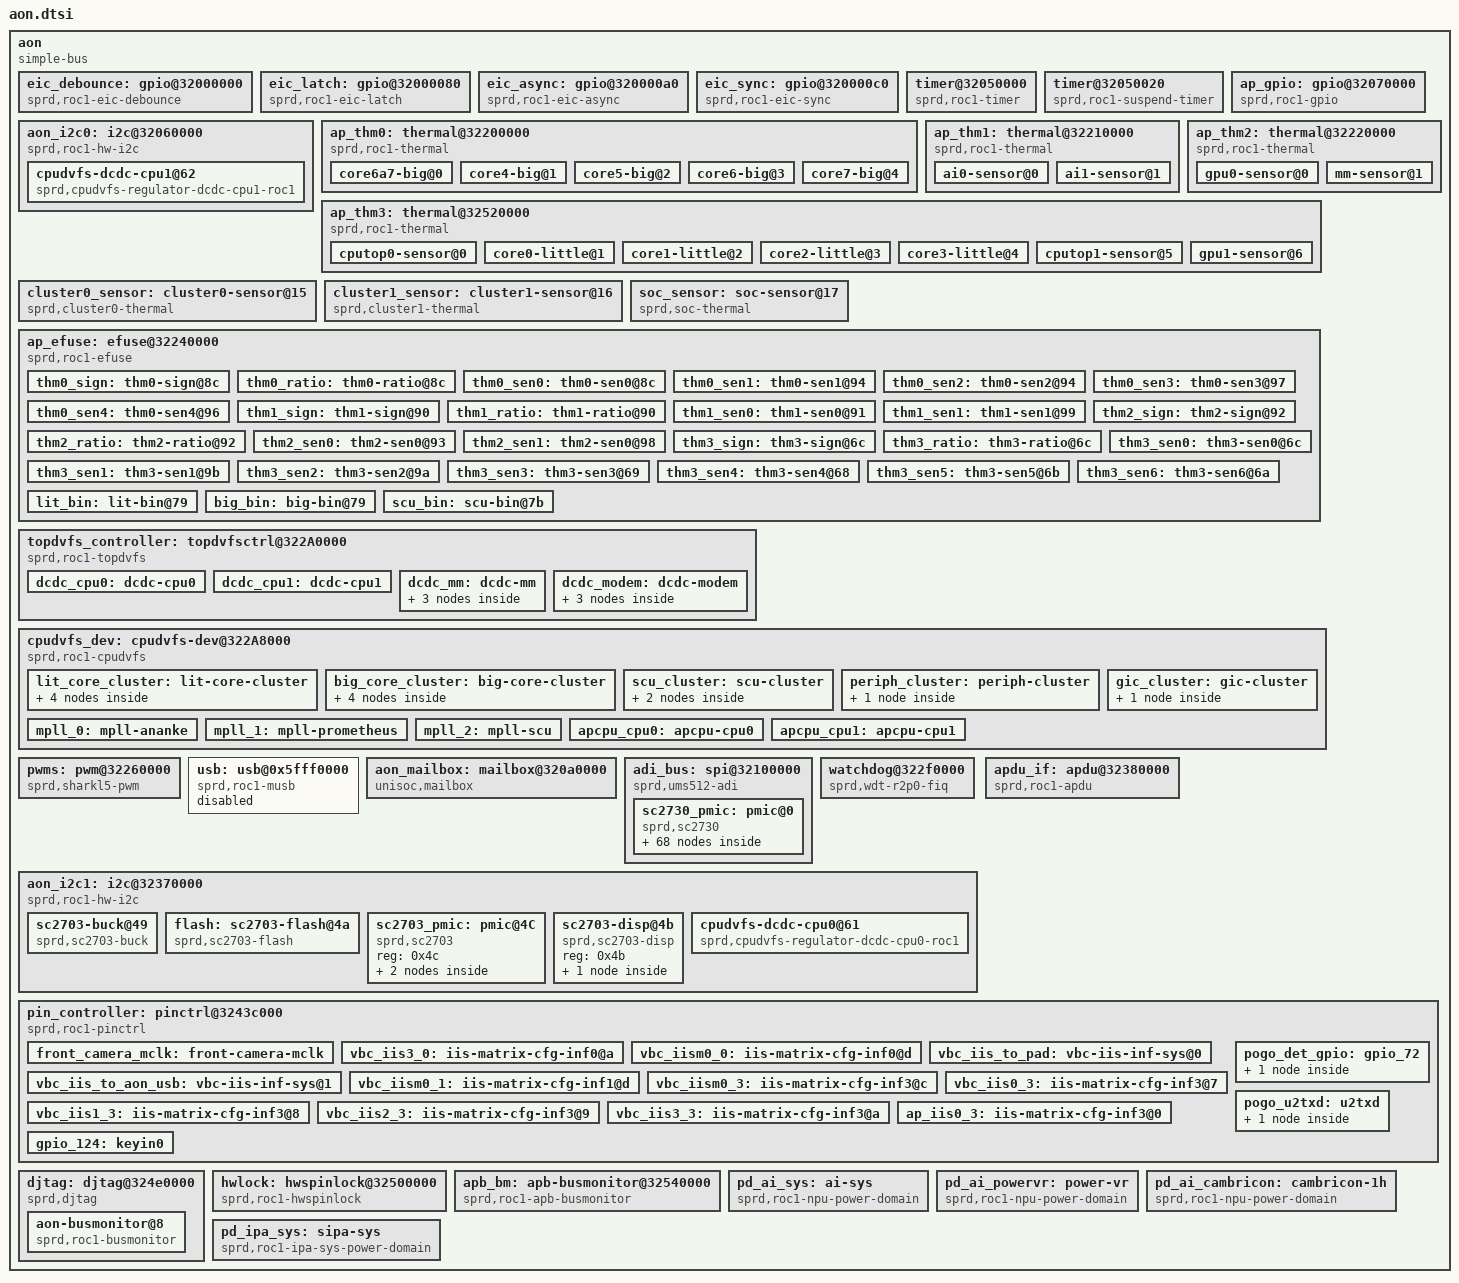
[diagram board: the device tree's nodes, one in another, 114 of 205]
/*
 * iclass-c8pro hardware description; included in place from the board DTS.
 * Copyright (C) 2026 Evarentha - Linux 5.15 board port changes.
 */

		aon {
			compatible = "simple-bus";
			#address-cells = <0x02>;
			#size-cells = <0x02>;
			ranges;

			eic_debounce: gpio@32000000 {
				compatible = "sprd,roc1-eic-debounce";
				reg = <0x00 0x32000000 0x00 0x80 0x00 0x32010000 0x00 0x80 0x00 0x32020000 0x00 0x80 0x00 0x32030000 0x00 0x80 0x00 0x32230000 0x00 0x80 0x00 0x32270000 0x00 0x80>;
				gpio-controller;
				#gpio-cells = <0x02>;
				interrupt-controller;
				#interrupt-cells = <0x02>;
				interrupts = <0x00 0x48 0x04>;
				phandle = <0x157>;
			};

			eic_latch: gpio@32000080 {
				compatible = "sprd,roc1-eic-latch";
				reg = <0x00 0x32000080 0x00 0x20 0x00 0x32010080 0x00 0x20 0x00 0x32020080 0x00 0x20 0x00 0x32030080 0x00 0x20 0x00 0x32230080 0x00 0x20 0x00 0x32270080 0x00 0x20>;
				gpio-controller;
				#gpio-cells = <0x02>;
				interrupt-controller;
				#interrupt-cells = <0x02>;
				interrupts = <0x00 0x48 0x04>;
				phandle = <0x158>;
			};

			eic_async: gpio@320000a0 {
				compatible = "sprd,roc1-eic-async";
				reg = <0x00 0x320000a0 0x00 0x20 0x00 0x320100a0 0x00 0x20 0x00 0x320200a0 0x00 0x20 0x00 0x320300a0 0x00 0x20 0x00 0x322300a0 0x00 0x20 0x00 0x322700a0 0x00 0x20>;
				gpio-controller;
				#gpio-cells = <0x02>;
				interrupt-controller;
				#interrupt-cells = <0x02>;
				interrupts = <0x00 0x48 0x04>;
				phandle = <0x35>;
			};

			eic_sync: gpio@320000c0 {
				compatible = "sprd,roc1-eic-sync";
				reg = <0x00 0x320000c0 0x00 0x20 0x00 0x320100c0 0x00 0x20 0x00 0x320200c0 0x00 0x20 0x00 0x320300c0 0x00 0x20 0x00 0x322300c0 0x00 0x20 0x00 0x322700c0 0x00 0x20>;
				gpio-controller;
				#gpio-cells = <0x02>;
				interrupt-controller;
				#interrupt-cells = <0x02>;
				interrupts = <0x00 0x48 0x04>;
				phandle = <0x159>;
			};

			timer@32050000 {
				compatible = "sprd,roc1-timer";
				reg = <0x00 0x32050000 0x00 0x20>;
				interrupts = <0x00 0x47 0x04>;
				clocks = <0x25>;
			};

			timer@32050020 {
				compatible = "sprd,roc1-suspend-timer";
				reg = <0x00 0x32050020 0x00 0x20>;
				clocks = <0x25>;
			};

			aon_i2c0: i2c@32060000 {
				compatible = "sprd,roc1-hw-i2c";
				reg = <0x00 0x32060000 0x00 0x1000>;
				interrupts = <0x00 0x44 0x04>;
				clock-names = "source", "enable", "i2c";
				clocks = <&ext_26m>, <&aonapb_gate 0x2c>,
					 <&aon_clk 0x11>;
				clock-frequency = <0x61a80>;
				#address-cells = <0x01>;
				#size-cells = <0x00>;
				status = "okay";
				phandle = <0x15a>;

				cpudvfs-dcdc-cpu1@62 {
					compatible = "sprd,cpudvfs-regulator-dcdc-cpu1-roc1";
					reg = <0x62>;
					dvfs-dcdc-i2c = <0x01>;
				};
			};

			ap_gpio: gpio@32070000 {
				compatible = "sprd,roc1-gpio";
				reg = <0x00 0x32070000 0x00 0x10000>;
				gpio-controller;
				#gpio-cells = <0x02>;
				interrupt-controller;
				#interrupt-cells = <0x02>;
				interrupts = <0x00 0x3d 0x04>;
				phandle = <0x2d>;
			};

			ap_thm0: thermal@32200000 {
				compatible = "sprd,roc1-thermal";
				reg = <0x00 0x32200000 0x00 0x10000>;
				clock-names = "enable";
				clocks = <0x04 0x28>;
				#thermal-sensor-cells = <0x01>;
				nvmem-cells = <0x3b 0x3c>;
				nvmem-cell-names = "thm_sign_cal", "thm_ratio_cal";
				phandle = <0x10c>;

				core6a7-big@0 {
					reg = <0x00>;
					nvmem-cells = <0x3d>;
					nvmem-cell-names = "sen_delta_cal";
				};

				core4-big@1 {
					reg = <0x01>;
					nvmem-cells = <0x3e>;
					nvmem-cell-names = "sen_delta_cal";
				};

				core5-big@2 {
					reg = <0x02>;
					nvmem-cells = <0x3f>;
					nvmem-cell-names = "sen_delta_cal";
				};

				core6-big@3 {
					reg = <0x03>;
					nvmem-cells = <0x40>;
					nvmem-cell-names = "sen_delta_cal";
				};

				core7-big@4 {
					reg = <0x04>;
					nvmem-cells = <0x41>;
					nvmem-cell-names = "sen_delta_cal";
				};
			};

			ap_thm1: thermal@32210000 {
				compatible = "sprd,roc1-thermal";
				reg = <0x00 0x32210000 0x00 0x10000>;
				clock-names = "enable";
				clocks = <0x04 0x29>;
				#thermal-sensor-cells = <0x01>;
				nvmem-cells = <0x42 0x43>;
				nvmem-cell-names = "thm_sign_cal", "thm_ratio_cal";
				phandle = <0x10d>;

				ai0-sensor@0 {
					reg = <0x00>;
					nvmem-cells = <0x44>;
					nvmem-cell-names = "sen_delta_cal";
				};

				ai1-sensor@1 {
					reg = <0x01>;
					nvmem-cells = <0x45>;
					nvmem-cell-names = "sen_delta_cal";
				};
			};

			ap_thm2: thermal@32220000 {
				compatible = "sprd,roc1-thermal";
				reg = <0x00 0x32220000 0x00 0x10000>;
				clock-names = "enable";
				clocks = <0x04 0x2a>;
				#thermal-sensor-cells = <0x01>;
				nvmem-cells = <0x46 0x47>;
				nvmem-cell-names = "thm_sign_cal", "thm_ratio_cal";
				phandle = <0x10e>;

				gpu0-sensor@0 {
					reg = <0x00>;
					nvmem-cells = <0x48>;
					nvmem-cell-names = "sen_delta_cal";
				};

				mm-sensor@1 {
					reg = <0x01>;
					nvmem-cells = <0x49>;
					nvmem-cell-names = "sen_delta_cal";
				};
			};

			ap_thm3: thermal@32520000 {
				compatible = "sprd,roc1-thermal";
				reg = <0x00 0x32520000 0x00 0x10000>;
				clock-names = "enable";
				clocks = <0x04 0x23>;
				#thermal-sensor-cells = <0x01>;
				nvmem-cells = <0x4a 0x4b>;
				nvmem-cell-names = "thm_sign_cal", "thm_ratio_cal";
				phandle = <0x10f>;

				cputop0-sensor@0 {
					reg = <0x00>;
					nvmem-cells = <0x4c>;
					nvmem-cell-names = "sen_delta_cal";
				};

				core0-little@1 {
					reg = <0x01>;
					nvmem-cells = <0x4d>;
					nvmem-cell-names = "sen_delta_cal";
				};

				core1-little@2 {
					reg = <0x02>;
					nvmem-cells = <0x4e>;
					nvmem-cell-names = "sen_delta_cal";
				};

				core2-little@3 {
					reg = <0x03>;
					nvmem-cells = <0x4f>;
					nvmem-cell-names = "sen_delta_cal";
				};

				core3-little@4 {
					reg = <0x04>;
					nvmem-cells = <0x50>;
					nvmem-cell-names = "sen_delta_cal";
				};

				cputop1-sensor@5 {
					reg = <0x05>;
					nvmem-cells = <0x51>;
					nvmem-cell-names = "sen_delta_cal";
				};

				gpu1-sensor@6 {
					reg = <0x06>;
					nvmem-cells = <0x52>;
					nvmem-cell-names = "sen_delta_cal";
				};
			};

			cluster0_sensor: cluster0-sensor@15 {
				compatible = "sprd,cluster0-thermal";
				#thermal-sensor-cells = <0x01>;
				sensor-names = "littlecore0-thmzone", "littlecore1-thmzone", "littlecore2-thmzone", "littlecore3-thmzone";
				k-po = <0x80>;
				k-pu = <0x100>;
				k-i = <0x02>;
				k-d = <0x00>;
				cutoff = <0x2710>;
				phandle = <0x110>;
			};

			cluster1_sensor: cluster1-sensor@16 {
				compatible = "sprd,cluster1-thermal";
				#thermal-sensor-cells = <0x01>;
				sensor-names = "bigcore4-thmzone", "bigcore5-thmzone", "bigcore6-thmzone", "bigcore7-thmzone";
				k-po = <0x80>;
				k-pu = <0x100>;
				k-i = <0x02>;
				k-d = <0x00>;
				cutoff = <0x2710>;
				phandle = <0x111>;
			};

			soc_sensor: soc-sensor@17 {
				compatible = "sprd,soc-thermal";
				#thermal-sensor-cells = <0x01>;
				sensor-names = "cluster0-thmzone", "cluster1-thmzone";
				k-po = <0x00>;
				k-pu = <0x00>;
				k-i = <0x02>;
				k-d = <0x00>;
				cutoff = <0x00>;
				phandle = <0x108>;
			};

			ap_efuse: efuse@32240000 {
				compatible = "sprd,roc1-efuse";
				reg = <0x00 0x32240000 0x00 0x10000>;
				clock-names = "enable";
				hwlocks = <0x53 0x08>;
				clocks = <0x04 0x13>;
				phandle = <0x15b>;

				thm0_sign: thm0-sign@8c {
					reg = <0x8c 0x04>;
					bits = <0x00 0x01>;
					phandle = <0x3b>;
				};

				thm0_ratio: thm0-ratio@8c {
					reg = <0x8c 0x04>;
					bits = <0x01 0x07>;
					phandle = <0x3c>;
				};

				thm0_sen0: thm0-sen0@8c {
					reg = <0x8d 0x04>;
					bits = <0x00 0x08>;
					phandle = <0x3d>;
				};

				thm0_sen1: thm0-sen1@94 {
					reg = <0x95 0x04>;
					bits = <0x00 0x08>;
					phandle = <0x3e>;
				};

				thm0_sen2: thm0-sen2@94 {
					reg = <0x94 0x04>;
					bits = <0x00 0x08>;
					phandle = <0x3f>;
				};

				thm0_sen3: thm0-sen3@97 {
					reg = <0x97 0x04>;
					bits = <0x00 0x08>;
					phandle = <0x40>;
				};

				thm0_sen4: thm0-sen4@96 {
					reg = <0x96 0x04>;
					bits = <0x00 0x08>;
					phandle = <0x41>;
				};

				thm1_sign: thm1-sign@90 {
					reg = <0x90 0x04>;
					bits = <0x00 0x01>;
					phandle = <0x42>;
				};

				thm1_ratio: thm1-ratio@90 {
					reg = <0x90 0x04>;
					bits = <0x01 0x07>;
					phandle = <0x43>;
				};

				thm1_sen0: thm1-sen0@91 {
					reg = <0x91 0x04>;
					bits = <0x00 0x08>;
					phandle = <0x44>;
				};

				thm1_sen1: thm1-sen1@99 {
					reg = <0x99 0x04>;
					bits = <0x00 0x08>;
					phandle = <0x45>;
				};

				thm2_sign: thm2-sign@92 {
					reg = <0x92 0x04>;
					bits = <0x00 0x01>;
					phandle = <0x46>;
				};

				thm2_ratio: thm2-ratio@92 {
					reg = <0x92 0x04>;
					bits = <0x01 0x07>;
					phandle = <0x47>;
				};

				thm2_sen0: thm2-sen0@93 {
					reg = <0x93 0x04>;
					bits = <0x00 0x08>;
					phandle = <0x48>;
				};

				thm2_sen1: thm2-sen0@98 {
					reg = <0x98 0x04>;
					bits = <0x00 0x08>;
					phandle = <0x49>;
				};

				thm3_sign: thm3-sign@6c {
					reg = <0x6c 0x04>;
					bits = <0x00 0x01>;
					phandle = <0x4a>;
				};

				thm3_ratio: thm3-ratio@6c {
					reg = <0x6c 0x04>;
					bits = <0x01 0x07>;
					phandle = <0x4b>;
				};

				thm3_sen0: thm3-sen0@6c {
					reg = <0x6d 0x04>;
					bits = <0x00 0x08>;
					phandle = <0x4c>;
				};

				thm3_sen1: thm3-sen1@9b {
					reg = <0x9b 0x04>;
					bits = <0x00 0x08>;
					phandle = <0x4d>;
				};

				thm3_sen2: thm3-sen2@9a {
					reg = <0x9a 0x04>;
					bits = <0x00 0x08>;
					phandle = <0x4e>;
				};

				thm3_sen3: thm3-sen3@69 {
					reg = <0x69 0x04>;
					bits = <0x00 0x08>;
					phandle = <0x4f>;
				};

				thm3_sen4: thm3-sen4@68 {
					reg = <0x68 0x04>;
					bits = <0x00 0x08>;
					phandle = <0x50>;
				};

				thm3_sen5: thm3-sen5@6b {
					reg = <0x6b 0x04>;
					bits = <0x00 0x08>;
					phandle = <0x51>;
				};

				thm3_sen6: thm3-sen6@6a {
					reg = <0x6a 0x04>;
					bits = <0x00 0x08>;
					phandle = <0x52>;
				};

				lit_bin: lit-bin@79 {
					reg = <0x79 0x01>;
					bits = <0x00 0x04>;
					phandle = <0xeb>;
				};

				big_bin: big-bin@79 {
					reg = <0x79 0x01>;
					bits = <0x04 0x04>;
					phandle = <0xec>;
				};

				scu_bin: scu-bin@7b {
					reg = <0x7b 0x01>;
					bits = <0x04 0x04>;
					phandle = <0xed>;
				};
			};

			topdvfs_controller: topdvfsctrl@322A0000 {
				compatible = "sprd,roc1-topdvfs", "syscon";
				sprd,syscon-enable = <0x10>;
				module-enable-cfg = <0x04 0x07>;
				reg = <0x00 0x322a0000 0x00 0x8000>;
				cpu-dcdc-cells = <0x54 0x55>;
				device-dcdc-cells = <0x56 0x57>;
				phandle = <0x60>;

				dcdc_cpu0: dcdc-cpu0 {
					dcdc-dvfs-enable = <0x90 0x00 0x01>;
					dcdc-judge-vol-sw = <0x150 0x0f 0x07 0x00>;
					dcdc-subsys-tune-enable = <0x300 0x02 0x01>;
					dcdc-supply-mode-cfg = <0x58>;
					sync-dcdc-idle-voltage;
					dcdc-idle-voltage = <0x320 0x06 0x07 0x05>;
					phandle = <0x54>;
				};

				dcdc_cpu1: dcdc-cpu1 {
					dcdc-dvfs-enable = <0xa0 0x00 0x01>;
					dcdc-judge-vol-sw = <0x160 0x0f 0x07 0x00>;
					dcdc-subsys-tune-enable = <0x300 0x01 0x01>;
					dcdc-supply-mode-cfg = <0x59>;
					sync-dcdc-idle-voltage;
					dcdc-idle-voltage = <0x320 0x03 0x07 0x05>;
					phandle = <0x55>;
				};

				dcdc_mm: dcdc-mm {
					dcdc-dvfs-enable = <0x18 0x14 0x01>;
					dcdc-judge-vol-sw = <0x18 0x01 0x07 0x02>;
					dcdc-subsys-cells = <0x5a 0x5b 0x5c>;
					phandle = <0x56>;

					audcp_sys: audcp-sys {
						dcdc-subsys-tune-enable = <0x300 0x06 0x01>;
						phandle = <0x5a>;
					};

					gpu_sys: gpu-sys {
						dcdc-subsys-tune-enable = <0x300 0x08 0x01>;
						phandle = <0x5b>;
					};

					mm_sys: mm-sys {
						dcdc-subsys-tune-enable = <0x300 0x07 0x01>;
						phandle = <0x5c>;
					};
				};

				dcdc_modem: dcdc-modem {
					dcdc-dvfs-enable = <0x48 0x14 0x01>;
					dcdc-judge-vol-sw = <0x48 0x01 0x07 0x02>;
					dcdc-subsys-cells = <0x5d 0x5e 0x5f>;
					phandle = <0x57>;

					pubcp_sys: pubcp-sys {
						dcdc-subsys-tune-enable = <0x300 0x03 0x00>;
						phandle = <0x5d>;
					};

					wtlcp_sys: wtlcp-sys {
						dcdc-subsys-tune-enable = <0x300 0x04 0x00>;
						phandle = <0x5e>;
					};

					ap_sys: ap-sys {
						dcdc-subsys-tune-enable = <0x300 0x05 0x01>;
						phandle = <0x5f>;
					};
				};
			};

			cpudvfs_dev: cpudvfs-dev@322A8000 {
				compatible = "sprd,roc1-cpudvfs";
				sprd,syscon-enable = <0x10>;
				module-enable-cfg = <0x04 0x07>;
				topdvfs-controller = <0x60>;
				reg = <0x00 0x322a8000 0x00 0x1000>;
				mpll-cells = <0x61 0x62 0x63>;
				apcpu-dvfs-dcdc-cells = <0x64 0x65>;
				cpudvfs-clusters = <0x66 0x67 0x68 0x69 0x6a>;
				phandle = <0x15c>;

				lit_core_cluster: lit-core-cluster {
					cluster-name = "lit-core-cluster";
					row-num = <0x10>;
					column-num = <0x07>;
					work-index-cfg = <0x214 0x0f>;
					idle-index-cfg = <0x218 0x0f>;
					tuning-latency-us = <0xc8>;
					tuning-result-judge = <0x00>;
					dcdc-name = "DCDC_CPU0";
					map-tbl-regs = <0x60 0x64 0x68 0x6c 0x70 0x74 0x78 0x7c 0x80 0x84 0x88 0x8c 0x90 0x94 0x98 0x9c>;
					column-entry-start-bit = <0x00 0x02 0x0f 0x05 0x09 0x12 0x0c>;
					column-entry-mask = <0x03 0x07 0x07 0x0f 0x07 0x07 0x07>;
					cluster-devices = <0x6b 0x6c 0x6d 0x6e>;
					lit-core-dvfs-tbl = <0x00 0x00 0x00 0x00 0x00 0x00 0x00 0x02 0x01 0x00 0x01 0x01 0x01 0x00 0x01 0x00 0x00 0x01 0x01 0x01 0x00 0x03 0x00 0x01 0x02 0x01 0x01 0x00 0x03 0x00 0x02 0x03 0x02 0x02 0x01 0x02 0x00 0x03 0x04 0x02 0x02 0x00 0x03 0x00 0x04 0x05 0x02 0x03 0x02 0x03 0x00 0x05 0x06 0x02 0x03 0x03 0x03 0x00 0x06 0x07 0x02 0x03 0x04 0x03 0x00 0x07 0x08 0x02 0x03 0x05 0x03 0x00 0x07 0x08 0x02 0x03 0x05 0x03 0x00 0x07 0x08 0x02 0x03 0x05 0x03 0x00 0x07 0x08 0x02 0x03 0x05 0x03 0x00 0x07 0x08 0x02 0x03 0x05 0x03 0x00 0x07 0x08 0x02 0x03 0x05 0x03 0x00 0x07 0x08 0x02 0x03 0x05>;
					lit-core-dvfs-tbl-1 = <0x00 0x00 0x00 0x00 0x00 0x00 0x00 0x02 0x01 0x00 0x01 0x01 0x01 0x00 0x01 0x00 0x00 0x01 0x01 0x01 0x00 0x03 0x00 0x00 0x02 0x01 0x01 0x00 0x03 0x00 0x00 0x03 0x02 0x02 0x01 0x02 0x00 0x01 0x04 0x02 0x02 0x00 0x03 0x00 0x02 0x05 0x02 0x03 0x02 0x03 0x00 0x03 0x06 0x02 0x03 0x03 0x03 0x00 0x04 0x07 0x02 0x03 0x04 0x03 0x00 0x05 0x08 0x02 0x03 0x05 0x03 0x00 0x05 0x08 0x02 0x03 0x05 0x03 0x00 0x05 0x08 0x02 0x03 0x05 0x03 0x00 0x05 0x08 0x02 0x03 0x05 0x03 0x00 0x05 0x08 0x02 0x03 0x05 0x03 0x00 0x05 0x08 0x02 0x03 0x05 0x03 0x00 0x05 0x08 0x02 0x03 0x05>;
					lit-core-dvfs-tbl-2 = <0x00 0x00 0x00 0x00 0x00 0x00 0x00 0x02 0x01 0x00 0x01 0x01 0x01 0x00 0x01 0x00 0x00 0x01 0x01 0x01 0x00 0x03 0x00 0x00 0x02 0x01 0x01 0x00 0x03 0x00 0x01 0x03 0x02 0x02 0x01 0x02 0x00 0x02 0x04 0x02 0x02 0x00 0x03 0x00 0x03 0x05 0x02 0x03 0x02 0x03 0x00 0x04 0x06 0x02 0x03 0x03 0x03 0x00 0x05 0x07 0x02 0x03 0x04 0x03 0x00 0x06 0x08 0x02 0x03 0x05 0x03 0x00 0x06 0x08 0x02 0x03 0x05 0x03 0x00 0x06 0x08 0x02 0x03 0x05 0x03 0x00 0x06 0x08 0x02 0x03 0x05 0x03 0x00 0x06 0x08 0x02 0x03 0x05 0x03 0x00 0x06 0x08 0x02 0x03 0x05 0x03 0x00 0x06 0x08 0x02 0x03 0x05>;
					lit-core-dvfs-tbl-3 = <0x00 0x00 0x00 0x00 0x00 0x00 0x00 0x02 0x01 0x00 0x01 0x01 0x01 0x00 0x01 0x00 0x00 0x01 0x01 0x01 0x00 0x03 0x00 0x00 0x02 0x01 0x01 0x00 0x03 0x00 0x01 0x03 0x02 0x02 0x01 0x02 0x00 0x02 0x04 0x02 0x02 0x00 0x03 0x00 0x03 0x05 0x02 0x03 0x02 0x03 0x00 0x04 0x06 0x02 0x03 0x03 0x03 0x00 0x05 0x07 0x02 0x03 0x04 0x03 0x00 0x06 0x08 0x02 0x03 0x05 0x03 0x00 0x06 0x08 0x02 0x03 0x05 0x03 0x00 0x06 0x08 0x02 0x03 0x05 0x03 0x00 0x06 0x08 0x02 0x03 0x05 0x03 0x00 0x06 0x08 0x02 0x03 0x05 0x03 0x00 0x06 0x08 0x02 0x03 0x05 0x03 0x00 0x06 0x08 0x02 0x03 0x05>;
					lit-core-dvfs-tbl-4 = <0x00 0x00 0x00 0x00 0x00 0x00 0x00 0x02 0x01 0x00 0x01 0x01 0x01 0x00 0x01 0x00 0x00 0x01 0x01 0x01 0x00 0x03 0x00 0x01 0x02 0x01 0x01 0x00 0x03 0x00 0x02 0x03 0x02 0x02 0x01 0x02 0x00 0x03 0x04 0x02 0x02 0x00 0x03 0x00 0x04 0x05 0x02 0x03 0x02 0x03 0x00 0x05 0x06 0x02 0x03 0x03 0x03 0x00 0x06 0x07 0x02 0x03 0x04 0x03 0x00 0x07 0x08 0x02 0x03 0x05 0x03 0x00 0x07 0x08 0x02 0x03 0x05 0x03 0x00 0x07 0x08 0x02 0x03 0x05 0x03 0x00 0x07 0x08 0x02 0x03 0x05 0x03 0x00 0x07 0x08 0x02 0x03 0x05 0x03 0x00 0x07 0x08 0x02 0x03 0x05 0x03 0x00 0x07 0x08 0x02 0x03 0x05>;
					phandle = <0x66>;

					lit_core0_dev: lit-core0-dev {
						device-name = "cpu0";
						sel-get = <0x38 0x00 0x03>;
						div-get = <0x38 0x02 0x07>;
						vol-get = <0x30 0x00 0x07>;
						dfs-idle-disable = <0x308 0x00 0x01>;
						phandle = <0x6b>;
					};

					lit_core1_dev: lit-core1-dev {
						device-name = "cpu1";
						sel-get = <0x38 0x05 0x03>;
						div-get = <0x38 0x07 0x07>;
						vol-get = <0x30 0x03 0x07>;
						dfs-idle-disable = <0x308 0x01 0x01>;
						phandle = <0x6c>;
					};

					lit_core2_dev: lit-core2-dev {
						device-name = "cpu2";
						sel-get = <0x38 0x0a 0x03>;
						div-get = <0x38 0x0c 0x07>;
						vol-get = <0x30 0x06 0x07>;
						dfs-idle-disable = <0x308 0x02 0x01>;
						phandle = <0x6d>;
					};

					lit_core3_dev: lit-core3-dev {
						device-name = "cpu3";
						sel-get = <0x38 0x0f 0x03>;
						div-get = <0x38 0x11 0x07>;
						vol-get = <0x30 0x09 0x07>;
						dfs-idle-disable = <0x308 0x03 0x01>;
						phandle = <0x6e>;
					};
				};

				big_core_cluster: big-core-cluster {
					cluster-name = "big-core-cluster";
					row-num = <0x10>;
					column-num = <0x08>;
					work-index-cfg = <0x224 0x0f>;
					idle-index-cfg = <0x228 0x0f>;
					tuning-latency-us = <0xc8>;
					tuning-result-judge = <0x00>;
					dcdc-name = "DCDC_CPU1";
					map-tbl-regs = <0xa0 0xa4 0xa8 0xac 0xb0 0xb4 0xb8 0xbc 0xc0 0xc4 0xc8 0xcc 0xd0 0xd4 0xd8 0xdc>;
					column-entry-start-bit = <0x00 0x02 0x0f 0x05 0x09 0x12 0x0c 0x15>;
					column-entry-mask = <0x03 0x07 0x07 0x0f 0x07 0x07 0x07 0x07>;
					cluster-devices = <0x6f 0x70 0x71 0x72>;
					big-core-dvfs-tbl = <0x00 0x00 0x00 0x00 0x00 0x00 0x00 0x00 0x01 0x00 0x00 0x03 0x02 0x00 0x00 0x02 0x03 0x00 0x01 0x05 0x02 0x00 0x00 0x03 0x03 0x00 0x02 0x07 0x02 0x00 0x01 0x03 0x03 0x00 0x03 0x08 0x02 0x00 0x02 0x03 0x03 0x00 0x04 0x08 0x02 0x00 0x03 0x03 0x03 0x00 0x05 0x08 0x02 0x00 0x04 0x03 0x03 0x00 0x05 0x08 0x02 0x00 0x04 0x03 0x03 0x00 0x05 0x08 0x02 0x00 0x04 0x03 0x03 0x00 0x05 0x08 0x02 0x00 0x04 0x03 0x03 0x00 0x05 0x08 0x02 0x00 0x04 0x03 0x03 0x00 0x05 0x08 0x02 0x00 0x04 0x03 0x03 0x00 0x05 0x08 0x02 0x00 0x04 0x03 0x03 0x00 0x05 0x08 0x02 0x00 0x04 0x03 0x03 0x00 0x05 0x08 0x02 0x00 0x04 0x03 0x03 0x00 0x05 0x08 0x02 0x00 0x04 0x03>;
					big-core-dvfs-tbl-1 = <0x00 0x00 0x00 0x00 0x00 0x00 0x00 0x00 0x01 0x00 0x00 0x03 0x02 0x00 0x00 0x02 0x03 0x00 0x01 0x05 0x02 0x00 0x00 0x03 0x03 0x00 0x02 0x07 0x02 0x00 0x01 0x03 0x03 0x00 0x03 0x08 0x02 0x00 0x02 0x03 0x03 0x00 0x04 0x08 0x02 0x00 0x03 0x03 0x03 0x00 0x05 0x08 0x02 0x00 0x04 0x03 0x03 0x00 0x05 0x08 0x02 0x00 0x04 0x03 0x03 0x00 0x05 0x08 0x02 0x00 0x04 0x03 0x03 0x00 0x05 0x08 0x02 0x00 0x04 0x03 0x03 0x00 0x05 0x08 0x02 0x00 0x04 0x03 0x03 0x00 0x05 0x08 0x02 0x00 0x04 0x03 0x03 0x00 0x05 0x08 0x02 0x00 0x04 0x03 0x03 0x00 0x05 0x08 0x02 0x00 0x04 0x03 0x03 0x00 0x05 0x08 0x02 0x00 0x04 0x03 0x03 0x00 0x05 0x08 0x02 0x00 0x04 0x03>;
					big-core-dvfs-tbl-2 = <0x00 0x00 0x00 0x00 0x00 0x00 0x00 0x00 0x01 0x00 0x00 0x03 0x02 0x00 0x00 0x02 0x03 0x00 0x01 0x05 0x02 0x00 0x00 0x03 0x03 0x00 0x02 0x07 0x02 0x00 0x01 0x03 0x03 0x00 0x03 0x08 0x02 0x00 0x02 0x03 0x03 0x00 0x04 0x08 0x02 0x00 0x03 0x03 0x03 0x00 0x05 0x08 0x02 0x00 0x04 0x03 0x03 0x00 0x05 0x08 0x02 0x00 0x04 0x03 0x03 0x00 0x05 0x08 0x02 0x00 0x04 0x03 0x03 0x00 0x05 0x08 0x02 0x00 0x04 0x03 0x03 0x00 0x05 0x08 0x02 0x00 0x04 0x03 0x03 0x00 0x05 0x08 0x02 0x00 0x04 0x03 0x03 0x00 0x05 0x08 0x02 0x00 0x04 0x03 0x03 0x00 0x05 0x08 0x02 0x00 0x04 0x03 0x03 0x00 0x05 0x08 0x02 0x00 0x04 0x03 0x03 0x00 0x05 0x08 0x02 0x00 0x04 0x03>;
					big-core-dvfs-tbl-3 = <0x00 0x00 0x00 0x00 0x00 0x00 0x00 0x00 0x01 0x00 0x00 0x03 0x02 0x00 0x00 0x02 0x03 0x00 0x01 0x05 0x02 0x00 0x00 0x03 0x03 0x00 0x02 0x07 0x02 0x00 0x01 0x03 0x03 0x00 0x03 0x08 0x02 0x00 0x02 0x03 0x03 0x00 0x04 0x08 0x02 0x00 0x03 0x03 0x03 0x00 0x05 0x08 0x02 0x00 0x04 0x03 0x03 0x00 0x05 0x08 0x02 0x00 0x04 0x03 0x03 0x00 0x05 0x08 0x02 0x00 0x04 0x03 0x03 0x00 0x05 0x08 0x02 0x00 0x04 0x03 0x03 0x00 0x05 0x08 0x02 0x00 0x04 0x03 0x03 0x00 0x05 0x08 0x02 0x00 0x04 0x03 0x03 0x00 0x05 0x08 0x02 0x00 0x04 0x03 0x03 0x00 0x05 0x08 0x02 0x00 0x04 0x03 0x03 0x00 0x05 0x08 0x02 0x00 0x04 0x03 0x03 0x00 0x05 0x08 0x02 0x00 0x04 0x03>;
					big-core-dvfs-tbl-4 = <0x00 0x00 0x00 0x00 0x00 0x00 0x00 0x00 0x01 0x00 0x00 0x03 0x02 0x00 0x00 0x02 0x03 0x00 0x01 0x05 0x02 0x00 0x00 0x03 0x03 0x00 0x02 0x07 0x02 0x00 0x01 0x03 0x03 0x00 0x03 0x08 0x02 0x00 0x02 0x03 0x03 0x00 0x04 0x08 0x02 0x00 0x03 0x03 0x03 0x00 0x05 0x08 0x02 0x00 0x04 0x03 0x03 0x00 0x05 0x08 0x02 0x00 0x04 0x03 0x03 0x00 0x05 0x08 0x02 0x00 0x04 0x03 0x03 0x00 0x05 0x08 0x02 0x00 0x04 0x03 0x03 0x00 0x05 0x08 0x02 0x00 0x04 0x03 0x03 0x00 0x05 0x08 0x02 0x00 0x04 0x03 0x03 0x00 0x05 0x08 0x02 0x00 0x04 0x03 0x03 0x00 0x05 0x08 0x02 0x00 0x04 0x03 0x03 0x00 0x05 0x08 0x02 0x00 0x04 0x03 0x03 0x00 0x05 0x08 0x02 0x00 0x04 0x03>;
					phandle = <0x67>;

					big_core0_dev: big-core0-dev {
						device-name = "cpu4";
						sel-get = <0x38 0x14 0x03>;
						div-get = <0x38 0x16 0x07>;
						vol-get = <0x30 0x0c 0x07>;
						dfs-idle-disable = <0x308 0x04 0x01>;
						phandle = <0x6f>;
					};

					big_core1_dev: big-core1-dev {
						device-name = "cpu5";
						sel-get = <0x38 0x19 0x03>;
						div-get = <0x38 0x1b 0x07>;
						vol-get = <0x30 0x0f 0x07>;
						dfs-idle-disable = <0x308 0x05 0x01>;
						phandle = <0x70>;
					};

					big_core2_dev: big-core2-dev {
						device-name = "cpu6";
						sel-get = <0x3c 0x00 0x03>;
						div-get = <0x3c 0x02 0x07>;
						vol-get = <0x30 0x12 0x07>;
						dfs-idle-disable = <0x308 0x06 0x01>;
						phandle = <0x71>;
					};

					big_core3_dev: big-core3-dev {
						device-name = "cpu7";
						sel-get = <0x3c 0x05 0x03>;
						div-get = <0x3c 0x07 0x07>;
						vol-get = <0x30 0x15 0x07>;
						dfs-idle-disable = <0x308 0x07 0x01>;
						phandle = <0x72>;
					};
				};

				scu_cluster: scu-cluster {
					cluster-name = "scu-cluster";
					row-num = <0x10>;
					column-num = <0x05>;
					work-index-cfg = <0x22c 0x0f>;
					idle-index-cfg = <0x230 0x0f>;
					dcdc-name = "DCDC_CPU0";
					tuning-func-cfg = <0x18 0x01>;
					map-tbl-regs = <0x180 0x184 0x188 0x18c 0x190 0x194 0x198 0x19c 0x1a0 0x1a4 0x1a8 0x1ac 0x1b0 0x1b4 0x1b8 0x1bc>;
					column-entry-start-bit = <0x00 0x03 0x0c 0x06 0x09>;
					column-entry-mask = <0x07 0x07 0x07 0x07 0x07>;
					cluster-devices = <0x73 0x74>;
					scu-dvfs-tbl = <0x00 0x00 0x00 0x00 0x00 0x04 0x00 0x00 0x01 0x00 0x04 0x00 0x01 0x01 0x01 0x01 0x00 0x02 0x01 0x00 0x04 0x00 0x03 0x01 0x02 0x04 0x00 0x04 0x01 0x03 0x04 0x00 0x05 0x01 0x03 0x04 0x00 0x06 0x01 0x04 0x04 0x00 0x07 0x01 0x05 0x04 0x00 0x07 0x01 0x05 0x04 0x00 0x07 0x01 0x05 0x04 0x00 0x07 0x01 0x05 0x04 0x00 0x07 0x01 0x05 0x04 0x00 0x07 0x01 0x05 0x04 0x00 0x07 0x01 0x05 0x04 0x00 0x07 0x01 0x05>;
					scu-dvfs-tbl-1 = <0x00 0x00 0x00 0x00 0x00 0x04 0x00 0x00 0x01 0x00 0x04 0x00 0x00 0x01 0x01 0x01 0x00 0x00 0x01 0x00 0x04 0x00 0x01 0x01 0x02 0x04 0x00 0x02 0x01 0x03 0x04 0x00 0x03 0x01 0x03 0x04 0x00 0x04 0x01 0x04 0x04 0x00 0x05 0x01 0x05 0x04 0x00 0x05 0x01 0x05 0x04 0x00 0x05 0x01 0x05 0x04 0x00 0x05 0x01 0x05 0x04 0x00 0x05 0x01 0x05 0x04 0x00 0x05 0x01 0x05 0x04 0x00 0x05 0x01 0x05 0x04 0x00 0x05 0x01 0x05>;
					scu-dvfs-tbl-2 = <0x00 0x00 0x00 0x00 0x00 0x04 0x00 0x00 0x01 0x00 0x04 0x00 0x00 0x01 0x01 0x01 0x00 0x01 0x01 0x00 0x04 0x00 0x02 0x01 0x02 0x04 0x00 0x03 0x01 0x03 0x04 0x00 0x04 0x01 0x03 0x04 0x00 0x05 0x01 0x04 0x04 0x00 0x06 0x01 0x05 0x04 0x00 0x06 0x01 0x05 0x04 0x00 0x06 0x01 0x05 0x04 0x00 0x06 0x01 0x05 0x04 0x00 0x06 0x01 0x05 0x04 0x00 0x06 0x01 0x05 0x04 0x00 0x06 0x01 0x05 0x04 0x00 0x06 0x01 0x05>;
					scu-dvfs-tbl-3 = <0x00 0x00 0x00 0x00 0x00 0x04 0x00 0x00 0x01 0x00 0x04 0x00 0x00 0x01 0x01 0x01 0x00 0x01 0x01 0x00 0x04 0x00 0x02 0x01 0x02 0x04 0x00 0x03 0x01 0x03 0x04 0x00 0x04 0x01 0x03 0x04 0x00 0x05 0x01 0x04 0x04 0x00 0x06 0x01 0x05 0x04 0x00 0x06 0x01 0x05 0x04 0x00 0x06 0x01 0x05 0x04 0x00 0x06 0x01 0x05 0x04 0x00 0x06 0x01 0x05 0x04 0x00 0x06 0x01 0x05 0x04 0x00 0x06 0x01 0x05 0x04 0x00 0x06 0x01 0x05>;
					scu-dvfs-tbl-4 = <0x00 0x00 0x00 0x00 0x00 0x04 0x00 0x00 0x01 0x00 0x04 0x00 0x01 0x01 0x01 0x01 0x00 0x02 0x01 0x00 0x04 0x00 0x03 0x01 0x02 0x04 0x00 0x04 0x01 0x03 0x04 0x00 0x05 0x01 0x03 0x04 0x00 0x06 0x01 0x04 0x04 0x00 0x07 0x01 0x05 0x04 0x00 0x07 0x01 0x05 0x04 0x00 0x07 0x01 0x05 0x04 0x00 0x07 0x01 0x05 0x04 0x00 0x07 0x01 0x05 0x04 0x00 0x07 0x01 0x05 0x04 0x00 0x07 0x01 0x05 0x04 0x00 0x07 0x01 0x05>;
					phandle = <0x68>;

					scu_dev: scu-dev {
						device-name = "scu";
						sel-get = <0x3c 0x0a 0x07>;
						div-get = <0x3c 0x0d 0x07>;
						vol-get = <0x34 0x00 0x07>;
						dfs-idle-disable = <0x308 0x08 0x01>;
						phandle = <0x73>;
					};

					ace_dev: ace-dev {
						device-name = "ace";
						sel-get = <0x3c 0x0a 0x07>;
						div-get = <0x3c 0x10 0x07>;
						vol-get = <0x34 0x00 0x07>;
						phandle = <0x74>;
					};
				};

				periph_cluster: periph-cluster {
					cluster-name = "periph-cluster";
					row-num = <0x08>;
					column-num = <0x03>;
					work-index-cfg = <0x23c 0x07>;
					idle-index-cfg = <0x240 0x07>;
					dcdc-name = "DCDC_CPU0";
					tuning-func-cfg = <0x18 0x00>;
					map-tbl-regs = <0x1f4 0x1f8 0x1fc 0x200 0x204 0x208 0x20c 0x210>;
					column-entry-start-bit = <0x00 0x02 0x05>;
					column-entry-mask = <0x03 0x07 0x07>;
					cluster-devices = <0x75>;
					periph-dvfs-tbl = <0x00 0x00 0x00 0x01 0x00 0x00 0x02 0x01 0x02 0x02 0x01 0x02 0x02 0x01 0x02 0x02 0x01 0x02 0x02 0x01 0x02 0x02 0x01 0x02>;
					periph-dvfs-tbl-1 = <0x00 0x00 0x00 0x01 0x00 0x00 0x02 0x01 0x00 0x02 0x01 0x00 0x02 0x01 0x00 0x02 0x01 0x00 0x02 0x01 0x00 0x02 0x01 0x00>;
					periph-dvfs-tbl-2 = <0x00 0x00 0x00 0x01 0x00 0x00 0x02 0x01 0x01 0x02 0x01 0x01 0x02 0x01 0x01 0x02 0x01 0x01 0x02 0x01 0x01 0x02 0x01 0x01>;
					periph-dvfs-tbl-3 = <0x00 0x00 0x00 0x01 0x00 0x00 0x02 0x01 0x01 0x02 0x01 0x01 0x02 0x01 0x01 0x02 0x01 0x01 0x02 0x01 0x01 0x02 0x01 0x01>;
					periph-dvfs-tbl-4 = <0x00 0x00 0x00 0x01 0x00 0x00 0x02 0x01 0x02 0x02 0x01 0x02 0x02 0x01 0x02 0x02 0x01 0x02 0x02 0x01 0x02 0x02 0x01 0x02>;
					phandle = <0x69>;

					periph_dev: periph-dev {
						device-name = "periph";
						sel-get = <0x3c 0x13 0x03>;
						div-get = <0x3c 0x15 0x07>;
						vol-get = <0x34 0x06 0x07>;
						dfs-idle-disable = <0x308 0x0a 0x01>;
						phandle = <0x75>;
					};
				};

				gic_cluster: gic-cluster {
					cluster-name = "gic-cluster";
					row-num = <0x08>;
					column-num = <0x03>;
					work-index-cfg = <0x2e0 0x07>;
					idle-index-cfg = <0x2e4 0x07>;
					dcdc-name = "DCDC_CPU0";
					tuning-func-cfg = <0x18 0x02>;
					map-tbl-regs = <0x280 0x284 0x288 0x28c 0x290 0x294 0x298 0x29c>;
					column-entry-start-bit = <0x00 0x02 0x05>;
					column-entry-mask = <0x03 0x07 0x07>;
					cluster-devices = <0x76>;
					gic-dvfs-tbl = <0x00 0x00 0x00 0x01 0x00 0x00 0x02 0x01 0x02 0x03 0x01 0x04 0x03 0x01 0x04 0x03 0x01 0x04 0x03 0x01 0x04 0x03 0x01 0x04>;
					gic-dvfs-tbl-1 = <0x00 0x00 0x00 0x01 0x00 0x00 0x02 0x01 0x00 0x03 0x01 0x02 0x03 0x01 0x02 0x03 0x01 0x02 0x03 0x01 0x02 0x03 0x01 0x02>;
					gic-dvfs-tbl-2 = <0x00 0x00 0x00 0x01 0x00 0x00 0x02 0x01 0x01 0x03 0x01 0x03 0x03 0x01 0x03 0x03 0x01 0x03 0x03 0x01 0x03 0x03 0x01 0x03>;
					gic-dvfs-tbl-3 = <0x00 0x00 0x00 0x01 0x00 0x00 0x02 0x01 0x01 0x03 0x01 0x03 0x03 0x01 0x03 0x03 0x01 0x03 0x03 0x01 0x03 0x03 0x01 0x03>;
					gic-dvfs-tbl-4 = <0x00 0x00 0x00 0x01 0x00 0x00 0x02 0x01 0x02 0x03 0x01 0x04 0x03 0x01 0x04 0x03 0x01 0x04 0x03 0x01 0x04 0x03 0x01 0x04>;
					phandle = <0x6a>;

					gic_dev: gic-dev {
						device-name = "gic";
						sel-get = <0x40 0x00 0x03>;
						div-get = <0x40 0x02 0x07>;
						vol-get = <0x34 0x09 0x07>;
						dfs-idle-disable = <0x308 0x0b 0x01>;
						phandle = <0x76>;
					};
				};

				mpll_0: mpll-ananke {
					sprd,syscon-ang = <0x77>;
					mpll-rst = <0x44 0x00 0x01 0x02>;
					relock-cfg = <0x244 0x01>;
					pd-cfg = <0x244 0x00>;
					phandle = <0x61>;
				};

				mpll_1: mpll-prometheus {
					sprd,syscon-ang = <0x78>;
					mpll-rst = <0x40 0x02 0x04 0x03>;
					relock-cfg = <0x258 0x01>;
					pd-cfg = <0x258 0x00>;
					phandle = <0x62>;
				};

				mpll_2: mpll-scu {
					sprd,syscon-ang = <0x79>;
					mpll-rst = <0x40 0x00 0x01 0x02>;
					relock-cfg = <0x26c 0x01>;
					pd-cfg = <0x26c 0x00>;
					phandle = <0x63>;
				};

				apcpu_cpu0: apcpu-cpu0 {
					subsys-dcdc-vol-sw = <0x20 0x04 0x07 0x00>;
					subsys-dvfs-state = <0x44 0x00 0x07>;
					phandle = <0x64>;
				};

				apcpu_cpu1: apcpu-cpu1 {
					subsys-dcdc-vol-sw = <0x24 0x04 0x07 0x00>;
					subsys-dvfs-state = <0x4c 0x00 0x07>;
					phandle = <0x65>;
				};
			};

			pwms: pwm@32260000 {
				compatible = "sprd,sharkl5-pwm", "sprd,roc1-pwm";
				reg = <0x00 0x32260000 0x00 0x10000>;
				status = "okay";
				clock-names = "pwm0", "enable0", "pwm1", "enable1",
					      "pwm2", "enable2", "pwm3", "enable3";
				clocks = <&aon_clk CLK_AON_PWM0>, <&aonapb_gate CLK_PWM0_EB>,
					 <&aon_clk CLK_AON_PWM1>, <&aonapb_gate CLK_PWM1_EB>,
					 <&aon_clk CLK_AON_PWM2>, <&aonapb_gate CLK_PWM2_EB>,
					 <&aon_clk CLK_AON_PWM3>, <&aonapb_gate CLK_PWM3_EB>;
				assigned-clocks = <&aon_clk CLK_AON_PWM0>, <&aon_clk CLK_AON_PWM1>,
						  <&aon_clk CLK_AON_PWM2>, <&aon_clk CLK_AON_PWM3>;
				assigned-clock-parents = <&ext_26m>, <&ext_26m>,
							 <&ext_26m>, <&ext_26m>;
				counter-bits = "10bit", "10bit", "10bit", "10bit";
				#pwm-cells = <0x02>;
				phandle = <0x15d>;
			};

			usb: usb@0x5fff0000 {
				compatible = "sprd,roc1-musb";
				reg = <0x00 0x5fff0000 0x00 0x2000>;
				interrupts = <0x00 0x45 0x04>;
				interrupt-names = "mc";
				clocks = <0x04 0x1b>;
				clock-names = "core_clk";
				usb-phy = <0x7c>;
				phy-names = "usb";
				dr-mode = "peripheral";
				extcon = <0x1c>;
				vbus-supply = <0x28>;
				status = "disabled";
				phandle = <0x15e>;
			};

			aon_mailbox: mailbox@320a0000 {
				compatible = "unisoc,mailbox";
				reg = <0x00 0x320a0000 0x00 0x8000 0x00 0x320a8000 0x00 0x8000>;
				reg-names = "inbox", "outbox";
				sprd,mailbox_clk = <&aon_apb_regs 0x04 0x04>;
				interrupts = <0x00 0x52 0x04 0x00 0x53 0x04 0x00 0x54 0x04>;
				interrupt-names = "inbox", "outbox", "oob-outbox";
				#mbox-cells = <0x02>;
				phandle = <0x15f>;
			};

			adi_bus: spi@32100000 {
				/* 5.15 spi-sprd-adi binding: the sharkl5 (= ums512) family
				 * ADI IP is matched by "sprd,ums512-adi"; ums512_data in the
				 * driver carries the same SC2730 constants the 4.14
				 * sharkl5_data had.  The factory DTB's legacy
				 * "sprd,sharkl5-adi"/"sprd,roc1-adi" strings are not in
				 * the 5.15 driver's match table. */
				compatible = "sprd,ums512-adi";
				reg = <0x00 0x32100000 0x00 0x100000>;
				#address-cells = <0x01>;
				#size-cells = <0x00>;
				sprd,hw-channels = <0x02 0x18cc 0x03 0x18cc 0x0d 0x1854 0x0f 0x1874 0x11 0x1844 0x13 0x1844 0x1e 0x1820 0x23 0x19b8 0x27 0x19ac>;
				phandle = <0x160>;

				sc2730_pmic: pmic@0 {
					compatible = "sprd,sc2730";
					reg = <0x00>;
					spi-max-frequency = <0x18cba80>;
					interrupt-controller;
					#interrupt-cells = <0x02>;
					#address-cells = <0x01>;
					#size-cells = <0x00>;
					interrupts = <0x00 0xad 0x04>;
					phandle = <0x7d>;

					bc1p2 {
						compatible = "sprd,sc2730-bc1p2";
					};

					led-controller@180 {
						compatible = "sprd,sc27xx-bltc", "sprd,sc2730-bltc";
						#address-cells = <0x01>;
						#size-cells = <0x00>;
						reg = <0x180>;

						led@0 {
							label = "red";
							reg = <0x00>;
						};

						led@1 {
							label = "green";
							reg = <0x01>;
						};

						led@2 {
							label = "blue";
							reg = <0x02>;
						};
					};

					rtc@200 {
						compatible = "sprd,sc27xx-rtc", "sprd,sc2730-rtc";
						reg = <0x200>;
						interrupt-parent = <0x7d>;
						interrupts = <0x01 0x04>;
					};

					pmic_eic: gpio@280 {
						compatible = "sprd,sc27xx-eic", "sprd,sc2730-eic";
						reg = <0x280>;
						interrupt-parent = <0x7d>;
						interrupts = <0x04 0x04>;
						gpio-controller;
						#gpio-cells = <0x02>;
						interrupt-controller;
						#interrupt-cells = <0x02>;
						phandle = <0x83>;
					};

					efuse@300 {
						compatible = "sprd,sc27xx-efuse", "sprd,sc2730-efuse";
						reg = <0x300>;
						#address-cells = <0x01>;
						#size-cells = <0x01>;
						hwlocks = <0x53 0x0c>;

						adc_bcal: calib@0 {
							reg = <0x24 0x02>;
							phandle = <0x81>;
						};

						adc_scal: calib@1 {
							reg = <0x26 0x02>;
							phandle = <0x82>;
						};

						pddelta_calib: calib@2 {
							reg = <0x02 0x02>;
							phandle = <0x87>;
						};

						pdrc_calib: calib@6 {
							reg = <0x06 0x02>;
							phandle = <0x86>;
						};

						pdref_calib: calib@1e {
							reg = <0x1e 0x02>;
							phandle = <0x88>;
						};

						fgu_calib: calib@3 {
							reg = <0x06 0x02>;
							phandle = <0x84>;
						};

						cc_cal: calib@d {
							reg = <0x1a 0x02>;
							phandle = <0x7e>;
						};

						aud_pabst_vcal: calib@20 {
							reg = <0x20 0x02>;
							phandle = <0x89>;
						};

						neg_cp_efuse: calib@22 {
							reg = <0x22 0x02>;
							phandle = <0x8a>;
						};

						headset_adc_fir: calib@14 {
							reg = <0x28 0x02>;
							phandle = <0x80>;
						};

						headset_adc_sec: calib@16 {
							reg = <0x2c 0x02>;
							phandle = <0x118>;
						};
					};

					pmic_typec: typec@380 {
						compatible = "sprd,sc27xx-typec", "sprd,sc2730-typec";
						interrupt-parent = <0x7d>;
						interrupts = <0x08 0x04>;
						reg = <0x380>;
						sprd,mode = <0x02>;
						/* Both CC fields share this SC2730 efuse word. */
						nvmem-cells = <0x7e>, <0x7e>;
						nvmem-cell-names = "typec_cc1_cal", "typec_cc2_cal";
						vddldo-supply = <0x7f>;
						status = "okay";
						phandle = <0x1c>;

						vconn: typec-vconn {
							regulator-name = "vconn";
							phandle = <0x161>;
						};
					};

					pmic_fchg: fchg@400 {
						compatible = "sprd,sc27xx-fast-chg", "sprd,sc2730-fast-charger";
						reg = <0x400>;
						interrupt-parent = <0x7d>;
						interrupts = <0x05 0x04>;
						nvmem-cell-names = "fchg_cur_calib";
						nvmem-cells = <0x80>;
						status = "okay";
						sprd,input-voltage-microvolt = <0x4c4b40>;
						phys = <0x26>;
						phandle = <0x162>;
					};

					pmic_adc: adc@504 {
						compatible = "sprd,sc27xx-adc", "sprd,sc2730-adc";
						reg = <0x504>;
						interrupt-parent = <0x7d>;
						interrupts = <0x00 0x04>;
						#io-channel-cells = <0x01>;
						hwlocks = <0x53 0x04>;
						nvmem-cells = <0x81 0x82>;
						nvmem-cell-names = "big_scale_calib", "small_scale_calib";
						phandle = <0x2a>;
					};

					pmic_fgu: fgu@c00 {
						compatible = "sprd,sc27xx-fgu", "sprd,sc2730-fgu";
						reg = <0xc00>;
						bat-detect-gpio = <0x83 0x03 0x00>;
						nvmem-cell-names = "fgu_calib";
						nvmem-cells = <0x84>;
						io-channels = <0x2a 0x00 0x2a 0x0e>;
						io-channel-names = "bat-temp", "charge-vol";
						sprd,comp-resistance-mohm = <0x14>;
						interrupt-parent = <0x7d>;
						interrupts = <0x03 0x04>;
						monitored-battery = <0x85 0x85>;
						/* 5.15 uses a fixed 20000 uOhm ideal resistance. */
						sprd,calib-resistance-micro-ohms = <0x2710>;
						phandle = <0x163>;
					};

					pmic_pd: pd@e00 {
						compatible = "sprd,sc27xx-pd", "sprd,sc2730-pd";
						reg = <0xe00 0x380>;
						interrupt-parent = <0x7d>;
						interrupts = <0x09 0x04>;
						extcon = <0x1c>;
						nvmem-cells = <0x86 0x87 0x88 0x7e>;
						nvmem-cell-names = "pdrc_calib", "pddelta_calib", "pdref_calib", "cc_calib";
						status = "disabled";
						phandle = <0x164>;

						usb_con: connector {
							compatible = "usb-c-connector";
							label = "USB-C";
							power-role = "dual";
							try-power-role = "sink";
							source-pdos = <0x4019028>;
							sink-pdos = <0x4019032 0x40190c8>;
							op-sink-microwatt = <0x989680>;
							phandle = <0x165>;
						};
					};

					sprd_audio_codec_ana: audio-codec@1000 {
						compatible = "sprd,sc2730-audio-codec", "sprd,sc27xx-audio-codec";
						#sound-dai-cells = <0x01>;
						reg = <0x1000>;
						sprd,syscon-pmu-apb = <0x02>;
						nvmem-cells = <0x89 0x8a 0x84>;
						nvmem-cell-names = "aud_pabst_vcal_efuse", "neg_cp_efuse", "fgu_4p2_efuse";
						status = "okay";
						hp-use-inter-pa = <0x01>;
						fixed-sample-rate = <0xbb80 0xbb80 0xbb80>;
						digital-codec = <0x8b>;
						phandle = <0x11f>;
					};

					syscon@1800 {
						compatible = "sprd,sc27xx-syscon";
						reg = <0x1800 0x1ba0 0x1b98>;
					};

					power-controller@1800 {
						compatible = "sprd,sc27xx-regulator", "sprd,sc2730-regulator";

						vddcpu: DCDC_CPU {
							regulator-name = "vddcpu";
							regulator-min-microvolt = <0x30d40>;
							regulator-max-microvolt = <0x185dcb>;
							regulator-ramp-delay = <0x61a8>;
							regulator-always-on;
							phandle = <0x166>;
						};

						vddgpu: DCDC_GPU {
							regulator-name = "vddgpu";
							regulator-min-microvolt = <0x30d40>;
							regulator-max-microvolt = <0x185dcb>;
							regulator-ramp-delay = <0x61a8>;
							regulator-always-on;
							phandle = <0x08>;
						};

						vddcore: DCDC_CORE {
							regulator-name = "vddcore";
							regulator-min-microvolt = <0x30d40>;
							regulator-max-microvolt = <0x185dcb>;
							regulator-ramp-delay = <0x61a8>;
							regulator-always-on;
							phandle = <0x167>;
						};

						vddmodem: DCDC_MODEM {
							regulator-name = "vddmodem";
							regulator-min-microvolt = <0x30d40>;
							regulator-max-microvolt = <0x185dcb>;
							regulator-ramp-delay = <0x61a8>;
							regulator-always-on;
							phandle = <0x168>;
						};

						vddmem: DCDC_MEM {
							regulator-name = "vddmem";
							regulator-min-microvolt = <0x61a80>;
							regulator-max-microvolt = <0x185196>;
							regulator-ramp-delay = <0x61a8>;
							regulator-always-on;
							phandle = <0x169>;
						};

						vddmemq: DCDC_MEMQ {
							regulator-name = "vddmemq";
							regulator-min-microvolt = <0x61a80>;
							regulator-max-microvolt = <0x185dcb>;
							regulator-ramp-delay = <0x61a8>;
							regulator-always-on;
							phandle = <0x16a>;
						};

						vddgen0: DCDC_GEN0 {
							regulator-name = "vddgen0";
							regulator-min-microvolt = <0x129da0>;
							regulator-max-microvolt = <0x24c881>;
							regulator-ramp-delay = <0x61a8>;
							regulator-always-on;
							phandle = <0x16b>;
						};

						vddgen1: DCDC_GEN1 {
							regulator-name = "vddgen1";
							regulator-min-microvolt = <0xcf850>;
							regulator-max-microvolt = <0x1914e6>;
							regulator-ramp-delay = <0x61a8>;
							regulator-always-on;
							phandle = <0x16c>;
						};

						vddsram: DCDC_SRAM {
							regulator-name = "vddsram";
							regulator-min-microvolt = <0x30d40>;
							regulator-max-microvolt = <0x185dcb>;
							regulator-ramp-delay = <0x61a8>;
							regulator-always-on;
							phandle = <0x16d>;
						};

						avdd18: LDO_AVDD18 {
							regulator-name = "avdd18";
							regulator-min-microvolt = <0x11edd8>;
							regulator-max-microvolt = <0x1b8ac8>;
							regulator-ramp-delay = <0x61a8>;
							regulator-always-on;
							phandle = <0x16e>;
						};

						vddrf18: LDO_VDDRF18 {
							regulator-name = "vddrf18";
							regulator-min-microvolt = <0x11edd8>;
							regulator-max-microvolt = <0x1b8ac8>;
							regulator-ramp-delay = <0x61a8>;
							status = "okay";
							phandle = <0x2f>;
						};

						vddcamio: LDO_VDDCAMIO {
							regulator-name = "vddcamio";
							regulator-min-microvolt = <0x124f80>;
							regulator-max-microvolt = <0x1bec70>;
							regulator-ramp-delay = <0x61a8>;
							phandle = <0x92>;
						};

						vddwcn: LDO_VDDWCN {
							regulator-name = "vddwcn";
							regulator-min-microvolt = <0xdbba0>;
							regulator-max-microvolt = <0x1c2708>;
							regulator-ramp-delay = <0x61a8>;
							regulator-always-on;
							phandle = <0x16f>;
						};

						vddcamd1: LDO_VDDCAMD1 {
							regulator-name = "vddcamd1";
							regulator-min-microvolt = <0xdbba0>;
							regulator-max-microvolt = <0x14d408>;
							regulator-ramp-delay = <0x61a8>;
							phandle = <0x98>;
						};

						vddcamd0: LDO_VDDCAMD0 {
							regulator-name = "vddcamd0";
							regulator-min-microvolt = <0xdbba0>;
							regulator-max-microvolt = <0x14d408>;
							regulator-ramp-delay = <0x61a8>;
							phandle = <0x94>;
						};

						vddrf1v25: LDO_VDDRF1V25 {
							regulator-name = "vddrf1v25";
							regulator-min-microvolt = <0xdbba0>;
							regulator-max-microvolt = <0x14d408>;
							regulator-ramp-delay = <0x61a8>;
							regulator-always-on;
							status = "disabled";
							phandle = <0x170>;
						};

						avdd12: LDO_AVDD12 {
							regulator-name = "avdd12";
							regulator-min-microvolt = <0xdbba0>;
							regulator-max-microvolt = <0x14d408>;
							regulator-ramp-delay = <0x61a8>;
							regulator-always-on;
							phandle = <0x171>;
						};

						vddcama0: LDO_VDDCAMA0 {
							regulator-name = "vddcama0";
							regulator-min-microvolt = <0x124f80>;
							regulator-max-microvolt = <0x393870>;
							regulator-ramp-delay = <0x61a8>;
							phandle = <0x93>;
						};

						vddcama1: LDO_VDDCAMA1 {
							regulator-name = "vddcama1";
							regulator-min-microvolt = <0x124f80>;
							regulator-max-microvolt = <0x393870>;
							regulator-ramp-delay = <0x61a8>;
							phandle = <0x97>;
						};

						vddcammot: LDO_VDDCAMMOT {
							regulator-name = "vddcammot";
							regulator-min-microvolt = <0x124f80>;
							regulator-max-microvolt = <0x393870>;
							regulator-ramp-delay = <0x61a8>;
							phandle = <0x95>;
						};

						vddsim2: LDO_VDDSIM2 {
							regulator-name = "vddsim2";
							regulator-min-microvolt = <0x124f80>;
							regulator-max-microvolt = <0x393870>;
							regulator-ramp-delay = <0x61a8>;
							status = "disabled";
							phandle = <0x172>;
						};

						vddemmccore: LDO_VDDEMMCCORE {
							regulator-name = "vddemmccore";
							regulator-min-microvolt = <0x124f80>;
							regulator-max-microvolt = <0x393870>;
							regulator-ramp-delay = <0x61a8>;
							phandle = <0x9c>;
						};

						vddsdcore: LDO_VDDSDCORE {
							regulator-name = "vddsdcore";
							regulator-min-microvolt = <0x124f80>;
							regulator-max-microvolt = <0x393870>;
							regulator-ramp-delay = <0x61a8>;
							regulator-always-on;
							phandle = <0x9d>;
						};

						vddsdio: LDO_VDDSDIO {
							regulator-name = "vddsdio";
							regulator-min-microvolt = <0x124f80>;
							regulator-max-microvolt = <0x393870>;
							regulator-ramp-delay = <0x61a8>;
							phandle = <0x9e>;
						};

						vdd28: LDO_VDD28 {
							regulator-name = "vdd28";
							regulator-min-microvolt = <0x124f80>;
							regulator-max-microvolt = <0x393870>;
							regulator-ramp-delay = <0x61a8>;
							regulator-always-on;
							phandle = <0x173>;
						};

						vddwifipa: LDO_VDDWIFIPA {
							regulator-name = "vddwifipa";
							regulator-min-microvolt = <0x124f80>;
							regulator-max-microvolt = <0x393870>;
							regulator-ramp-delay = <0x61a8>;
							phandle = <0x174>;
						};

						vdd18_dcxo: LDO_VDD18_DCXO {
							regulator-name = "vdd18_dcxo";
							regulator-min-microvolt = <0x124f80>;
							regulator-max-microvolt = <0x393870>;
							regulator-ramp-delay = <0x61a8>;
							regulator-always-on;
							phandle = <0x175>;
						};

						vddusb33: LDO_VDDUSB33 {
							regulator-name = "vddusb33";
							regulator-min-microvolt = <0x124f80>;
							regulator-max-microvolt = <0x393870>;
							regulator-ramp-delay = <0x61a8>;
							phandle = <0x1b>;
						};

						vddldo0: LDO_VDDLDO0 {
							regulator-name = "vddldo0";
							regulator-min-microvolt = <0x124f80>;
							regulator-max-microvolt = <0x393870>;
							regulator-ramp-delay = <0x61a8>;
							phandle = <0x176>;
						};

						vddldo1: LDO_VDDLDO1 {
							regulator-name = "vddldo1";
							regulator-min-microvolt = <0x124f80>;
							regulator-max-microvolt = <0x393870>;
							regulator-ramp-delay = <0x61a8>;
							regulator-boot-on;
							phandle = <0x177>;
						};

						vddldo2: LDO_VDDLDO2 {
							regulator-name = "vddldo2";
							regulator-min-microvolt = <0x124f80>;
							regulator-max-microvolt = <0x393870>;
							regulator-ramp-delay = <0x61a8>;
							phandle = <0x7f>;
						};

						vddkpled: LDO_VDDKPLED {
							regulator-name = "vddkpled";
							regulator-min-microvolt = <0x124f80>;
							regulator-max-microvolt = <0x393870>;
							regulator-ramp-delay = <0x61a8>;
							phandle = <0x178>;
						};
					};

					poweroff@1820 {
						compatible = "sprd,sc27xx-poweroff", "sprd,sc2730-poweroff";
						reg = <0x1820>;
					};

					pmic_tsensor: tsensor@1b34 {
						compatible = "sprd,sc27xx-tsensor", "sprd,sc2730-tsensor";
						#thermal-sensor-cells = <0x01>;
						reg = <0x1b34>;
						phandle = <0x179>;

						osc_tsensor: osc-tsensor@0 {
							reg = <0x00>;
							phandle = <0x17a>;
						};

						tout_tsensor: tout-tsensor@1 {
							reg = <0x01>;
							phandle = <0x17b>;
						};
					};

					led-controller@1b88 {
						compatible = "sprd,sc27xx-keypad-led", "sprd,sc2730-keypad-led";
						reg = <0x1b88 0x1b8c>;
					};

					vibrator@1b90 {
						compatible = "sprd,sc27xx-vibrator", "sprd,sc2730-vibrator";
						reg = <0x1b90>;
					};

					hw_reset@1bc0 {
						compatible = "sprd,sc27xx-7sreset", "sprd,sc2730-7sreset";
						reg = <0x1bf8 0x1bc0>;
					};
				};
			};

			watchdog@322f0000 {
				compatible = "sprd,wdt-r2p0-fiq";
				reg = <0x00 0x322f0000 0x00 0x10000>;
				interrupts = <0x00 0x4f 0x04>;
				timeout-sec = <0x0c>;
				clock-names = "enable", "rtc_enable";
				clocks = <0x04 0x3f 0x04 0x49>;
			};

			aon_i2c1: i2c@32370000 {
				compatible = "sprd,roc1-hw-i2c";
				reg = <0x00 0x32370000 0x00 0x1000>;
				interrupts = <0x00 0x83 0x04>;
				clock-names = "source", "enable", "i2c", "clk_hw_i2c";
				clock-frequency = <0x61a80>;
				#address-cells = <0x01>;
				#size-cells = <0x00>;
				status = "okay";
				phandle = <0x17c>;

				sc2703-buck@49 {
					compatible = "sprd,sc2703-buck";
					reg = <0x49>;
					buck-gpios = <0x2d 0x84 0x01>;
					sprd,buck-ch1-b-out = <0xf4240>;
					regulator-name = "sc2703-buck";
					regulator-min-microvolt = <0x493e0>;
					regulator-max-microvolt = <0x17f4d0>;
					regulator-min-microamp = "", "Us";
					regulator-max-microamp = <0xa4cb80>;
					regulator-boot-on;
					regulator-always-on;
				};

				flash: sc2703-flash@4a {
					compatible = "sprd,sc2703-flash";
					reg = <0x4a>;
					flash-chip-en-gpios = <0x2d 0x8f 0x00>;
					phandle = <0x17d>;
				};

				sc2703_pmic: pmic@4C {
					compatible = "sprd,sc2703";
					reg = <0x4c>;
					phandle = <0x17e>;

					sc2703-charger {
						compatible = "sprd,sc2703-charger";
						phys = <0x26>;
						monitored-battery = <0x85 0x85>;
						extcon = <0x1c>;
						sprd,long-key-detection;

						vddvbus: otg-vbus {
							regulator-name = "vddvbus";
							phandle = <0x28>;
						};
					};
				};

				sc2703-disp@4b {
					compatible = "sprd,sc2703-disp";
					reg = <0x4b>;

					lcd_vdd: lcd-regulator {
						compatible = "sprd,sc2703-lcd-regulator";
						regulator-name = "sc2703-lcd";
						regulator-boot-on;
						phandle = <0x2e>;
					};
				};

				cpudvfs-dcdc-cpu0@61 {
					compatible = "sprd,cpudvfs-regulator-dcdc-cpu0-roc1";
					reg = <0x61>;
					dvfs-dcdc-i2c = <0x00>;
				};
			};

			apdu_if: apdu@32380000 {
				compatible = "sprd,roc1-apdu";
				reg = <0x00 0x32380000 0x00 0x10000>;
				interrupts = <0x00 0xbb 0x04>;
				phandle = <0x17f>;
			};

			pin_controller: pinctrl@3243c000 {
				compatible = "sprd,roc1-pinctrl";
				reg = <0x00 0x3243c000 0x00 0x20000>;
				pinctrl-names = "gpio_124";
				pinctrl-1 = <0x8c>;
				phandle = <0x115>;

				front_camera_mclk: front-camera-mclk {
					pins = "ROC1_CMMCLK2";
					function = "func1";
				};

				vbc_iis3_0: iis-matrix-cfg-inf0@a {
					pins = "ROC1_IIS_INF0_SYS_SEL";
					sprd,control = <0x0a>;
					phandle = <0xa3>;
				};

				vbc_iism0_0: iis-matrix-cfg-inf0@d {
					pins = "ROC1_IIS_INF0_SYS_SEL";
					sprd,control = <0x0d>;
					phandle = <0xa4>;
				};

				vbc_iis_to_pad: vbc-iis-inf-sys@0 {
					pins = "ROC1_VBC_IIS_INF_SYS_SEL";
					sprd,control = <0x00>;
					phandle = <0xa5>;
				};

				vbc_iis_to_aon_usb: vbc-iis-inf-sys@1 {
					pins = "ROC1_VBC_IIS_INF_SYS_SEL";
					sprd,control = <0x01>;
					phandle = <0xa6>;
				};

				vbc_iism0_1: iis-matrix-cfg-inf1@d {
					pins = "ROC1_IIS_INF1_SYS_SEL";
					sprd,control = <0x0d>;
					phandle = <0xa7>;
				};

				vbc_iism0_3: iis-matrix-cfg-inf3@c {
					pins = "ROC1_IIS_INF3_SYS_SEL";
					sprd,control = <0x0c>;
					phandle = <0xa8>;
				};

				vbc_iis0_3: iis-matrix-cfg-inf3@7 {
					pins = "ROC1_IIS_INF3_SYS_SEL";
					sprd,control = <0x07>;
					phandle = <0xa9>;
				};

				vbc_iis1_3: iis-matrix-cfg-inf3@8 {
					pins = "ROC1_IIS_INF3_SYS_SEL";
					sprd,control = <0x08>;
					phandle = <0xaa>;
				};

				vbc_iis2_3: iis-matrix-cfg-inf3@9 {
					pins = "ROC1_IIS_INF3_SYS_SEL";
					sprd,control = <0x09>;
					phandle = <0xab>;
				};

				vbc_iis3_3: iis-matrix-cfg-inf3@a {
					pins = "ROC1_IIS_INF3_SYS_SEL";
					sprd,control = <0x0a>;
					phandle = <0xac>;
				};

				ap_iis0_3: iis-matrix-cfg-inf3@0 {
					pins = "ROC1_IIS_INF3_SYS_SEL";
					sprd,control = <0x00>;
					phandle = <0xad>;
				};

				pogo_det_gpio: gpio_72 {
					pins = "ROC1_U2TXD";
					function = "func4";
					phandle = <0x90>;

					pogo_det_gpio_misc: gpio_72_config {
						pins = "ROC1_U2TXD_MISC";
						phandle = <0x180>;
					};
				};

				pogo_u2txd: u2txd {
					pins = "ROC1_U2TXD";
					function = "func1";
					phandle = <0x91>;

					pogo_u2txd_misc: u2txd_config {
						pins = "ROC1_U2TXD_MISC";
						phandle = <0x181>;
					};
				};

				gpio_124: keyin0 {
					pins = "ROC1_KEYIN0";
					function = "func4";
					phandle = <0x8c>;
				};
			};

			djtag: djtag@324e0000 {
				compatible = "sprd,djtag";
				reg = <0x00 0x324e0000 0x00 0x1000>;
				syscon-names = "soft_rst";
				syscons = <0x10 0x130 0x400>;
				clock-names = "enable", "tck";
				clocks = <0x04 0x02 0x04 0x01>;
				hwlocks = <0x53 0x0a>;
				hwlock-names = "djtag";
				#address-cells = <0x01>;
				#size-cells = <0x00>;
				phandle = <0x182>;

				aon-busmonitor@8 {
					compatible = "sprd,roc1-busmonitor";
					interrupts = <0x00 0x51 0x04>;
					reg = <0x08>;
					sprd,bm-num = <0x06>;
					sprd,bm-name = "AP", "WTLCP", "AUDCP", "PUBCP", "USBOTG", "CM4";
					sprd,bm-type = <0x01 0x01 0x01 0x01 0x01 0x01>;
					sprd,bm-dap = <0x00 0x01 0x02 0x03 0x04 0x05>;
					sprd,bm-config = <0x01 0x01 0x01 0x01 0x01 0x01 0x01 0x01 0x01 0x01 0x01 0x01 0x00 0x01 0x01 0x01 0x01 0x01>;
					sprd,bm-id = <0x00 0x00 0x00 0x00 0x00 0x00 0x00 0x00 0x00 0x00 0x00 0x00 0x00 0x00 0x00 0x00 0x00 0x00>;
					sprd,bm-ranges = <0x5ffe0000 0x5ffe0018 0x5ffe0000 0x5ffe0018 0x5ffe0000 0x5ffe0018 0xffe0000 0xffe0018 0x00 0x00 0x5ffe0000 0x5ffe0018>;
				};
			};

			hwlock: hwspinlock@32500000 {
				compatible = "sprd,roc1-hwspinlock";
				reg = <0x00 0x32500000 0x00 0x10000>;
				#hwlock-cells = <0x01>;
				clock-names = "enable";
				clocks = <0x04 0x1d>;
				phandle = <0x53>;
			};

			apb_bm: apb-busmonitor@32540000 {
				compatible = "sprd,roc1-apb-busmonitor";
				reg = <0x00 0x32540000 0x00 0x1000>;
				interrupts = <0x00 0x66 0x04>;
				sprd,target-addr = <0x00 0x00>;
				sprd,target-data = <0x00 0x00>;
				phandle = <0x183>;
			};

			pd_ai_sys: ai-sys {
				compatible = "sprd,roc1-npu-power-domain";
				syscons = <0x02 0x530 0x2000000>;
				syscon-names = "cfg";
				phandle = <0x8d>;
			};

			pd_ai_powervr: power-vr {
				compatible = "sprd,roc1-npu-power-domain";
				syscons = <0x02 0x52c 0x2000000>;
				syscon-names = "cfg";
				sprd,pd-ai = <0x8d>;
				phandle = <0xaf>;
			};

			pd_ai_cambricon: cambricon-1h {
				compatible = "sprd,roc1-npu-power-domain";
				syscons = <0x02 0x534 0x2000000>;
				syscon-names = "cfg";
				sprd,pd-ai = <0x8d>;
				phandle = <0xb0>;
			};

			pd_ipa_sys: sipa-sys {
				compatible = "sprd,roc1-ipa-sys-power-domain";
				reg-size = <13>;
				ipa-sys-forcewakeup = <&pmu_apb_regs 0x25c 0xff>;
				ipa-sys-forceshutdown = <&pmu_apb_regs 0x538 0x2000000>;
				ipa-sys-autoshutdown = <&pmu_apb_regs 0x538 0x1000000>;
				ipa-sys-forcedslp = <&pmu_apb_regs 0x544 0x40>;
				ipa-sys-dslpen = <&pmu_apb_regs 0x22c 0x01>;
				ipa-sys-forcelslp = <&pmu_apb_regs 0x548 0x40>;
				ipa-sys-lslpen = <&pmu_apb_regs 0x230 0x40>;
				ipa-sys-smartlslpen = <&pmu_apb_regs 0x230 0x20000>;
				ipa-sys-ipaeb = <&ipa_ahb_regs 0x04 0x08>;
				ipa-sys-cm4eb = <&ipa_ahb_regs 0x04 0x20000>;
				ipa-sys-autogaten = <&ipa_ahb_regs 0x34 0x20000>;
				ipa-sys-s5-autogaten = <&ipa_ahb_regs 0x4c 0x20000>;
				ipa-sys-pwr-state = <&pmu_apb_regs 0x580 0xff000000>;
				#power-domain-cells = <0x00>;
				clocks = <0x24 0x00 0x07 0x16 0x7a>;
				clock-names = "ipa_core", "ipa_core_source", "ipa_core_default";
				phandle = <0x17>;
			};
		};

